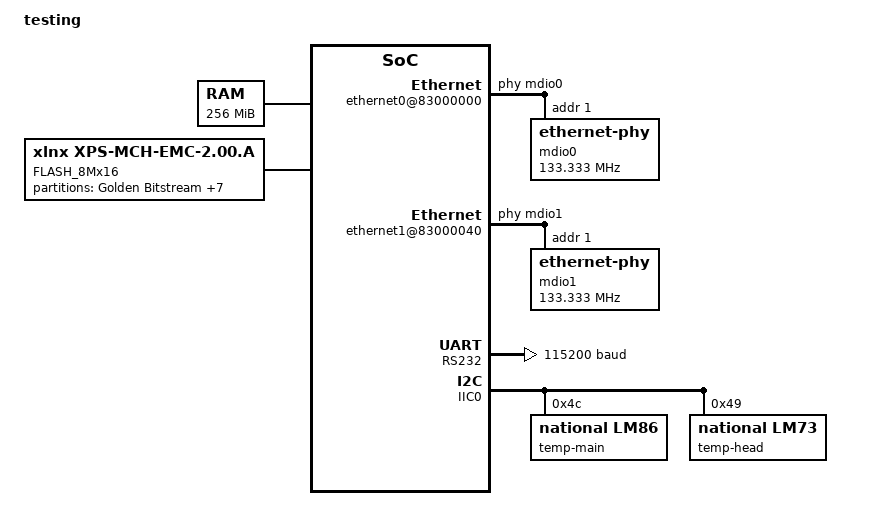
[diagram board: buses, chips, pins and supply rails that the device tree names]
/*
 * Device Tree Generator version: 1.1
 *
 * (C) Copyright 2007-2008 Xilinx, Inc.
 * (C) Copyright 2007-2008 Michal Simek
 *
 * Michal SIMEK <monstr@monstr.eu>
 *
 * This program is free software; you can redistribute it and/or
 * modify it under the terms of the GNU General Public License as
 * published by the Free Software Foundation; either version 2 of
 * the License, or (at your option) any later version.
 *
 * This program is distributed in the hope that it will be useful,
 * but WITHOUT ANY WARRANTY; without even the implied warranty of
 * MERCHANTABILITY or FITNESS FOR A PARTICULAR PURPOSE. See the
 * GNU General Public License for more details.
 *
 * You should have received a copy of the GNU General Public License
 * along with this program; if not, write to the Free Software
 * Foundation, Inc., 59 Temple Place, Suite 330, Boston,
 * MA 02111-1307 USA
 *
 * CAUTION: This file is automatically generated by libgen.
 * Version: Xilinx EDK 10.1.03 EDK_K_SP3.6
 *
 * XPS project directory: base_design_sp3
 */

/dts-v1/;
/ {
	#address-cells = <1>;
	#size-cells = <1>;
	compatible = "xlnx,virtex440", "xlnx,virtex";
	dcr-parent = <&ppc440_0>;
	model = "testing";
	DDR2_SDRAM_16Mx32: memory@0 {
		device_type = "memory";
		reg = < 0x0 0x10000000 >;
	} ;
	chosen {
		bootargs = "console=ttyUL0 root=ubi0_0 rootfstype=ubifs ubi.mtd=6 rw";
		/*bootargs = "console=ttyUL0 root=/dev/ram";*/
		linux,stdout-path = "/plb@0/serial@8B000000";
	} ;
	aliases {
		ethernet0 ="/plb/ethernet0";
		ethernet1 ="/plb/ethernet1";
	} ;
	cpus {
		#address-cells = <1>;
		#cpus = <0x1>;
		#size-cells = <0>;
		ppc440_0: cpu@0 {
			#address-cells = <1>;
			#size-cells = <1>;
			clock-frequency = <400000000>;
			compatible = "PowerPC,440", "ibm,ppc440";
			d-cache-line-size = <0x20>;
			d-cache-size = <0x8000>;
			dcr-access-method = "native";
			dcr-controller ;
			device_type = "cpu";
			i-cache-line-size = <0x20>;
			i-cache-size = <0x8000>;
			model = "PowerPC,440";
			reg = <0>;
			timebase-frequency = <400000000>;
			DMA0: sdma@80 {
				compatible = "xlnx,ll-dma-1.00.a";
				dcr-reg = < 0x80 0x11 >;
				interrupt-parent = <&xps_intc_0>;
				interrupts = < 1 2 2 2 >;
			} ;
			DMA1: sdma@98 {
				compatible = "xlnx,ll-dma-1.00.a";
				dcr-reg = < 0x98 0x11 >;
				interrupt-parent = <&xps_intc_0>;
				interrupts = < 4 2 5 2 >;
			} ;
		} ;
	} ;

	plb_v46_0: plb@0 {
		#address-cells = <1>;
		#size-cells = <1>;
		compatible = "xlnx,plb-v46-1.03.a", "simple-bus";
		ranges;
		FLASH_8Mx16: flash@f0000000 {
			#address-cells = <1>;
			#size-cells = <1>;
			bank-width = <2>;
			compatible = "xlnx,xps-mch-emc-2.00.a", "cfi-flash";
			/*Remember to change u-boot config and OE config if you change this*/
			reg = < 0xf0000000 0x8000000 >;
			full@f0000000 {
				compatible = "partition";
				reg = < 0x000000 0x8000000 >;
				label = "Full FLASH";
			};
			partition@f0000000 {
				reg = < 0x000000 0x400000 >;
				label = "Golden Bitstream";
			};
			partition@f0400000 {
				reg = < 0x400000 0x400000 >;
				label = "Scratch Bitstream";
			};
			partition@f0800000 {
				reg = < 0x800000 0x400000 >;
				label = "Boot Bitstream";
			};
			partition@f0c00000 {
				reg = < 0x0c00000 0x400000 >;
				label = "Golden Linux";
			};
			partition@f1000000 {
				reg = < 0x1000000 0x100000 >;
				label = "Golden U-boot";
			};
			partition@f1100000 {
				reg = < 0x1100000 0x6de0000 >;
				label = "UBI Partition";
			};
			partition@f7ee0000 {
				reg = < 0x7ee0000 0x20000 >;
				label = "Das U-Boot Environment";
			};
			partition@f7f00000 {
				reg = < 0x7f00000 0x100000 >;
				label = "Das U-Boot";
			};
		} ;
		ethernet0@83000000 {
			#address-cells = <1>;
			#size-cells = <1>;
			compatible = "xlnx,xps-ll-temac-1.01.b";
			device_type = "network";
			interrupt-parent = <&xps_intc_0>;
			interrupts = < 3 2 >;
			llink-connected = <&DMA0>;
			local-mac-address = [ 00 fa ba da 02 00 ];
			reg = < 0x83000000 0x40 >;
			xlnx,bus2core-clk-ratio = <0x1>;
			xlnx,phy-type = <0x1>;
			xlnx,phyaddr = <0x1>;
			xlnx,rxcsum = <0x1>;
			xlnx,rxfifo = <0x1000>;
			xlnx,temac-type = <0x0>;
			xlnx,txcsum = <0x1>;
			xlnx,txfifo = <0x1000>;
			phy-handle = <&mdio0>;
			mdio0: ethernet-phy@1{
				reg = <1 0x1>;
				/*interrupts = < 3 2 >;*/
				clock-frequency = < 133333333 >;
			};
		};
		ethernet1@83000040 {
			#address-cells = <1>;
			#size-cells = <1>;
			compatible = "xlnx,xps-ll-temac-1.01.b";
			device_type = "network";
			interrupt-parent = <&xps_intc_0>;
			interrupts = < 6 2 >;
			llink-connected = <&DMA1>;
			local-mac-address = [ 00 fa ba da 02 01 ];
			reg = < 0x83000040 0x40 >;
			xlnx,bus2core-clk-ratio = <0x1>;
			xlnx,phy-type = <0x1>;
			xlnx,phyaddr = <0x1>;
			xlnx,rxcsum = <0x1>;
			xlnx,rxfifo = <0x1000>;
			xlnx,temac-type = <0x0>;
			xlnx,txcsum = <0x1>;
			xlnx,txfifo = <0x1000>;
			phy-handle = <&mdio1>;
			mdio1: ethernet-phy@1{
				reg = <1 0x1>;
				/*interrupts = < 6 2 >;*/
				clock-frequency = < 133333333 >;
			};
		} ;
		RS232: serial@8B000000 {
			#address-cells = <1>;
			#size-cells = <1>;
			clock-frequency = <100000000>;
			compatible = "xlnx,xps-uartlite-1.00.a";
			current-speed = <115200>;
			device_type = "serial";
			interrupt-parent = <&xps_intc_0>;
			interrupts = < 0 0 >;
			port-number = <0>;
			reg = < 0x8B000000 0x10000 >;
			xlnx,baudrate = <0x1c200>;
			xlnx,data-bits = <0x8>;
			xlnx,family = "virtex5";
			xlnx,odd-parity = <0x0>;
			xlnx,use-parity = <0x0>;
		} ;
		xps_sd_if_0: xps-sd-if@86800000 {
			#address-cells = <1>;
			#size-cells = <1>;
			compatible = "qtec,xps_sd-if-1.00.a";
			reg = < 0x86800000 0x10000 >;
			interrupt-parent = <&xps_intc_0>;
			interrupts = < 15 2 >;
			base-freq =  <133333333> ;
		};
		xps_intc_0: interrupt-controller@87000000 {
			#address-cells = <1>;
			#size-cells = <1>;
			#interrupt-cells = <0x2>;
			compatible = "xlnx,xps-intc-1.00.a";
			interrupt-controller ;
			reg = < 0x87000000 0x10000 >;
			xlnx,num-intr-inputs = <0x20>;
		} ;

		IIC0: i2c@84000000 {
			#address-cells = <1>;
			#size-cells = <1>;
		   	compatible = "xlnx,xps-iic-2.00.a";
		   	interrupt-parent = <&xps_intc_0>;
		   	interrupts = < 7 2 >;
		   	reg = < 0x84000000 0x10000 >;
		   	xlnx,clk-freq = <0x5f5e100>;
		   	xlnx,family = "virtex5";
		   	xlnx,gpo-width = <0x1>;
		   	xlnx,iic-freq = <0x186a0>;
		   	xlnx,scl-inertial-delay = <0x0>;
		   	xlnx,sda-inertial-delay = <0x0>;
		   	xlnx,ten-bit-adr = <0x0>;
			temp-main@4c {
				compatible = "national,lm86";
				reg = <0x4c 0x4c>;
			};
			temp-head@49 {
				compatible = "national,lm73";
				reg = <0x49 0x49>;
			};
	   	} ;
	   };
}  ;
